AUTOSAR XML (schema 314)
package /ComponentType
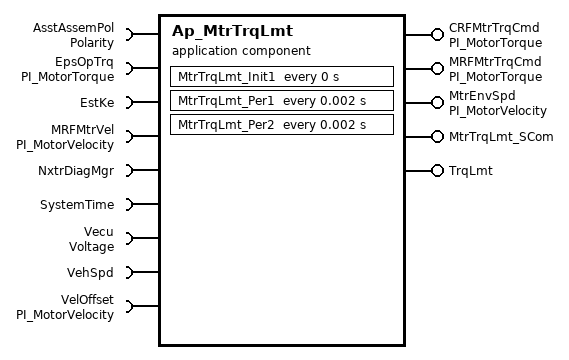
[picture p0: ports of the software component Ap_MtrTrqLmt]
  application software component type Ap_MtrTrqLmt
    5 x provide port:
      CRFMtrTrqCmd: unqueued-sender-com-spec{data-element=MtrNm_f32, can-invalidate=false, init-value=D_FLOATZERO_ULS_F32}, provided-interface=PI_MotorTorque
      MRFMtrTrqCmd: unqueued-sender-com-spec{data-element=MtrNm_f32, can-invalidate=false, init-value=D_FLOATZERO_ULS_F32}, provided-interface=PI_MotorTorque
      MtrEnvSpd: unqueued-sender-com-spec{data-element=MtrRadpS_f32, can-invalidate=false, init-value=D_FLOATZERO_ULS_F32}, provided-interface=PI_MotorVelocity
      MtrTrqLmt_SCom: provided-interface=MtrTrqLmt_SCom
        provided-com-specs:
          operation=ManualTrqCmd, queue-length=1
          operation=ReadEOLTrqCmdSclFac, queue-length=1
          operation=SetEOLTrqCmdSclFac, queue-length=1
      TrqLmt: unqueued-sender-com-spec{data-element=Pct_f32, can-invalidate=false, init-value=D_FLOATZERO_ULS_F32}, provided-interface=TrqLmt
    9 x require port:
      AsstAssemPol: unqueued-receiver-com-spec{data-element=Cnt_s8, init-value=D_SIGNED8ZERO_CNT_S8}, required-interface=Polarity
      EpsOpTrq: unqueued-receiver-com-spec{data-element=MtrNm_f32, init-value=D_FLOATZERO_ULS_F32}, required-interface=PI_MotorTorque
      EstKe: unqueued-receiver-com-spec{data-element=VpRadpS_f32, init-value=D_FLOATZERO_ULS_F32}, required-interface=EstKe
      MRFMtrVel: unqueued-receiver-com-spec{data-element=MtrRadpS_f32, init-value=D_FLOATZERO_ULS_F32}, required-interface=PI_MotorVelocity
      NxtrDiagMgr: required-com-specs=[GetNTCFailed, GetNTCStatus, ResetEventStatus, SetNTCStatus, SetOperationCycleState], required-interface=NxtrDiagMgr
      SystemTime: required-interface=SystemTime
        required-com-specs:
          DtrmnElapsedTime_mS_u16
          DtrmnElapsedTime_mS_u32
          DtrmnElapsedTime_uS_u16
          DtrmnElapsedTime_uS_u32
          GetSystemTime_mS_u32
          GetSystemTime_uS_u32
      Vecu: unqueued-receiver-com-spec{data-element=Volt_f32, init-value=D_VECUMIN_VOLTS_F32}, required-interface=Voltage
      VehSpd: unqueued-receiver-com-spec{data-element=Kph_f32, init-value=D_FLOATZERO_ULS_F32}, required-interface=VehSpd
      VelOffset: unqueued-receiver-com-spec{data-element=MtrRadpS_f32, init-value=D_FLOATZERO_ULS_F32}, required-interface=PI_MotorVelocity
  internal behavior Ap_MtrTrqLmt_InternalBehavior: component=Ap_MtrTrqLmt
    timing event MtrTrqLmt_Init1_InitEvent: start-on-event=MtrTrqLmt_Init1, period=0
    timing event TMT_MtrTrqLmt_Per1: start-on-event=MtrTrqLmt_Per1, period=0.002
    timing event TMT_MtrTrqLmt_Per2: start-on-event=MtrTrqLmt_Per2, period=0.002
    operation invoked event OIT_MtrTrqLmt_SCom_ManualTrqCmd_MtrTrqLmt_SCom_ManualTrqCmd: start-on-event=MtrTrqLmt_SCom_ManualTrqCmd, operation=MtrTrqLmt_SCom.ManualTrqCmd
    operation invoked event OIT_MtrTrqLmt_SCom_ReadEOLTrqCmdSclFac_MtrTrqLmt_SCom_ReadEOLTrqCmdSclFac: start-on-event=MtrTrqLmt_SCom_ReadEOLTrqCmdSclFac, operation=MtrTrqLmt_SCom.ReadEOLTrqCmdSclFac
    operation invoked event OIT_MtrTrqLmt_SCom_SetEOLTrqCmdSclFac_MtrTrqLmt_SCom_SetEOLTrqCmdSclFac: start-on-event=MtrTrqLmt_SCom_SetEOLTrqCmdSclFac, operation=MtrTrqLmt_SCom.SetEOLTrqCmdSclFac
    6 x inter runnable variable, all with sw-calibration-access=READ-ONLY:
      InvKeStdTemp_RadpSpV_f32: type=Float, communication-approach=EXPLICIT, init-value=D_FLOATZERO_ULS_F32
      ManualTrqCmd_MtrNm_f32: type=Float, communication-approach=EXPLICIT, init-value=D_FLOATZERO_ULS_F32
      ManualTrqCmdEn_Cnt_lgc: type=Boolean, communication-approach=EXPLICIT, init-value=D_BOOLEANFALSE_CNT_LGC
      StdOpTrqEnvLmt_MtrNm_u5p11: type=UInt16, communication-approach=IMPLICIT, init-value=D_UNSIGNED16ZERO_CNT_U16
      TrqEnvDiff_MtrNm_s4p11: type=SInt16, communication-approach=IMPLICIT, init-value=D_SIGNED16ZERO_CNT_S16
      TrqLmt_MtrNm_u5p11: type=UInt16, communication-approach=IMPLICIT, init-value=D_UNSIGNED16ZERO_CNT_U16
    port-api-options:
      enable-take-address=false, indirect-api=false, port=AsstAssemPol
      enable-take-address=false, indirect-api=false, port=CRFMtrTrqCmd
      enable-take-address=false, indirect-api=false, port=EpsOpTrq
      enable-take-address=false, indirect-api=false, port=EstKe
      enable-take-address=false, indirect-api=false, port=MRFMtrTrqCmd
      enable-take-address=false, indirect-api=false, port=MRFMtrVel
      enable-take-address=false, indirect-api=false, port=MtrEnvSpd
      enable-take-address=false, indirect-api=false, port=MtrTrqLmt_SCom
      enable-take-address=false, indirect-api=false, port=NxtrDiagMgr
      enable-take-address=false, indirect-api=false, port=SystemTime
      enable-take-address=false, indirect-api=false, port=TrqLmt
      enable-take-address=false, indirect-api=false, port=Vecu
      enable-take-address=false, indirect-api=false, port=VehSpd
      enable-take-address=false, indirect-api=false, port=VelOffset
    6 x runnable:
      MtrTrqLmt_Init1: written-variable=InvKeStdTemp_RadpSpV_f32
      MtrTrqLmt_Per1: read-variable=InvKeStdTemp_RadpSpV_f32, written-variable=[StdOpTrqEnvLmt_MtrNm_u5p11, TrqEnvDiff_MtrNm_s4p11, TrqLmt_MtrNm_u5p11]
        4 x data read access:
          READ_EstKe_VpRadpS_f32: data-element=EstKe.VpRadpS_f32
          READ_MRFMtrVel_MtrRadpS_f32: data-element=MRFMtrVel.MtrRadpS_f32
          READ_Vecu_Volt_f32: data-element=Vecu.Volt_f32
          READ_VelOffset_MtrRadpS_f32: data-element=VelOffset.MtrRadpS_f32
        data write access WRITE_MtrEnvSpd_MtrRadpS_f32: data-element=MtrEnvSpd.MtrRadpS_f32
        sync call SC_SystemTime_DtrmnElapsedTime_mS_u16: operation=SystemTime.DtrmnElapsedTime_mS_u16, timeout=0
        sync call SC_SystemTime_GetSystemTime_mS_u32: operation=SystemTime.GetSystemTime_mS_u32, timeout=0
      MtrTrqLmt_Per2: read-variable=[ManualTrqCmdEn_Cnt_lgc, ManualTrqCmd_MtrNm_f32, StdOpTrqEnvLmt_MtrNm_u5p11, TrqEnvDiff_MtrNm_s4p11, TrqLmt_MtrNm_u5p11]
        4 x data read access:
          READ_AsstAssemPol_Cnt_s8: data-element=AsstAssemPol.Cnt_s8
          READ_EpsOpTrq_MtrNm_f32: data-element=EpsOpTrq.MtrNm_f32
          READ_Vecu_Volt_f32: data-element=Vecu.Volt_f32
          READ_VehSpd_Kph_f32: data-element=VehSpd.Kph_f32
        data write access WRITE_CRFMtrTrqCmd_MtrNm_f32: data-element=CRFMtrTrqCmd.MtrNm_f32
        data write access WRITE_MRFMtrTrqCmd_MtrNm_f32: data-element=MRFMtrTrqCmd.MtrNm_f32
        data write access WRITE_TrqLmt_Pct_f32: data-element=TrqLmt.Pct_f32
        sync call SC_NxtrDiagMgr_SetNTCStatus: operation=NxtrDiagMgr.SetNTCStatus, timeout=0
      MtrTrqLmt_SCom_ManualTrqCmd: written-variable=[ManualTrqCmdEn_Cnt_lgc, ManualTrqCmd_MtrNm_f32]
        data receive point REC_VehSpd_Kph_f32: data-element=VehSpd.Kph_f32
      MtrTrqLmt_SCom_ReadEOLTrqCmdSclFac
      MtrTrqLmt_SCom_SetEOLTrqCmdSclFac
    service-needss:
      swc nv block needs EOLTrqCmdSclFac: n-data-sets=0, readonly=false, reliability=LOW, resistant-to-changed-sw=false, restore-at-start=true, write-only-once=false, writing-frequency=0, writing-priority=LOW
  swc implementation Ap_MtrTrqLmt_Implementation: behavior=Ap_MtrTrqLmt_InternalBehavior
    code-descriptors:
      code Code: type=SRC
